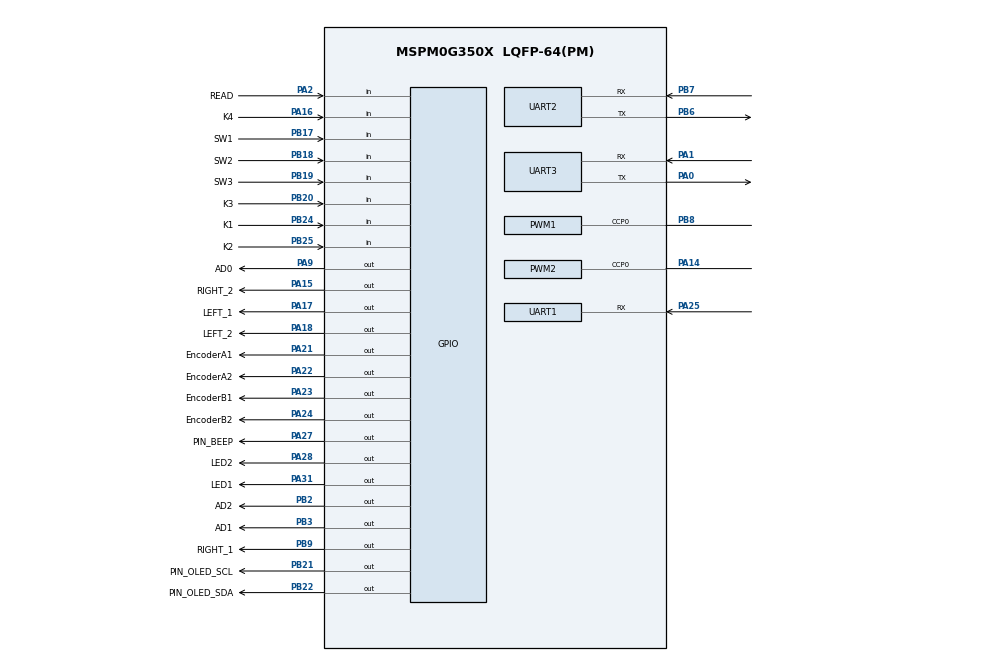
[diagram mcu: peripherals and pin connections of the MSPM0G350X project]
/**
 * @cliArgs --device "MSPM0G350X" --part "Default" --package "LQFP-64(PM)" --product "mspm0_sdk@2.10.00.04"
 * @versions {"tool":"1.26.2+4477"}
 */

/**
 * Import the modules used in this configuration.
 */
const GPIO   = scripting.addModule("/ti/driverlib/GPIO", {}, false);
const GPIO1  = GPIO.addInstance();
const GPIO2  = GPIO.addInstance();
const GPIO3  = GPIO.addInstance();
const GPIO4  = GPIO.addInstance();
const GPIO5  = GPIO.addInstance();
const GPIO6  = GPIO.addInstance();
const GPIO7  = GPIO.addInstance();
const GPIO8  = GPIO.addInstance();
const PWM    = scripting.addModule("/ti/driverlib/PWM", {}, false);
const PWM1   = PWM.addInstance();
const PWM2   = PWM.addInstance();
const SYSCTL = scripting.addModule("/ti/driverlib/SYSCTL");
const UART   = scripting.addModule("/ti/driverlib/UART", {}, false);
const UART1  = UART.addInstance();
const UART2  = UART.addInstance();
const UART3  = UART.addInstance();

/**
 * Write custom configuration values to the imported modules.
 */
const divider7       = system.clockTree["PLL_PDIV"];
divider7.divideValue = 2;

const divider9       = system.clockTree["UDIV"];
divider9.divideValue = 2;

const multiplier2         = system.clockTree["PLL_QDIV"];
multiplier2.multiplyValue = 5;

const mux8       = system.clockTree["HSCLKMUX"];
mux8.inputSelect = "HSCLKMUX_SYSPLL2X";

GPIO1.$name                          = "GPIO_MOTOR";
GPIO1.associatedPins.create(4);
GPIO1.associatedPins[0].$name        = "LEFT_1";
GPIO1.associatedPins[0].initialValue = "SET";
GPIO1.associatedPins[0].pin.$assign  = "PA17";
GPIO1.associatedPins[1].$name        = "LEFT_2";
GPIO1.associatedPins[1].pin.$assign  = "PA18";
GPIO1.associatedPins[2].$name        = "RIGHT_1";
GPIO1.associatedPins[2].pin.$assign  = "PB9";
GPIO1.associatedPins[3].$name        = "RIGHT_2";
GPIO1.associatedPins[3].pin.$assign  = "PA15";

const Board = scripting.addModule("/ti/driverlib/Board", {}, false);

GPIO2.$name                         = "GPIO_Grayscale";
GPIO2.associatedPins.create(4);
GPIO2.associatedPins[0].$name       = "READ";
GPIO2.associatedPins[0].direction   = "INPUT";
GPIO2.associatedPins[0].pin.$assign = "PA2";
GPIO2.associatedPins[1].$name       = "AD0";
GPIO2.associatedPins[1].pin.$assign = "PA9";
GPIO2.associatedPins[2].$name       = "AD1";
GPIO2.associatedPins[2].pin.$assign = "PB3";
GPIO2.associatedPins[3].$name       = "AD2";
GPIO2.associatedPins[3].pin.$assign = "PB2";

GPIO3.$name                         = "GPIO_BEEP";
GPIO3.associatedPins[0].$name       = "PIN_BEEP";
GPIO3.associatedPins[0].pin.$assign = "PA27";

GPIO4.$name                         = "GPIO_LED";
GPIO4.associatedPins.create(2);
GPIO4.associatedPins[0].$name       = "LED1";
GPIO4.associatedPins[0].pin.$assign = "PA31";
GPIO4.associatedPins[1].$name       = "LED2";
GPIO4.associatedPins[1].pin.$assign = "PA28";

GPIO5.$name                         = "GPIO_EncoderA";
GPIO5.associatedPins.create(2);
GPIO5.associatedPins[0].$name       = "EncoderA1";
GPIO5.associatedPins[0].pin.$assign = "PA21";
GPIO5.associatedPins[1].$name       = "EncoderA2";
GPIO5.associatedPins[1].pin.$assign = "PA22";

GPIO6.$name                         = "GPIO_EncoderB";
GPIO6.associatedPins.create(2);
GPIO6.associatedPins[0].$name       = "EncoderB1";
GPIO6.associatedPins[0].pin.$assign = "PA23";
GPIO6.associatedPins[1].$name       = "EncoderB2";
GPIO6.associatedPins[1].pin.$assign = "PA24";

GPIO7.$name                         = "GPIO_OLED";
GPIO7.associatedPins.create(2);
GPIO7.associatedPins[0].$name       = "PIN_OLED_SCL";
GPIO7.associatedPins[0].pin.$assign = "PB21";
GPIO7.associatedPins[1].$name       = "PIN_OLED_SDA";
GPIO7.associatedPins[1].pin.$assign = "PB22";

GPIO8.$name                         = "GPIO_KEY";
GPIO8.associatedPins.create(7);
GPIO8.associatedPins[0].$name       = "SW1";
GPIO8.associatedPins[0].direction   = "INPUT";
GPIO8.associatedPins[0].pin.$assign = "PB17";
GPIO8.associatedPins[1].$name       = "SW2";
GPIO8.associatedPins[1].direction   = "INPUT";
GPIO8.associatedPins[1].pin.$assign = "PB18";
GPIO8.associatedPins[2].$name       = "SW3";
GPIO8.associatedPins[2].direction   = "INPUT";
GPIO8.associatedPins[2].pin.$assign = "PB19";
GPIO8.associatedPins[3].$name       = "K1";
GPIO8.associatedPins[3].direction   = "INPUT";
GPIO8.associatedPins[3].pin.$assign = "PB24";
GPIO8.associatedPins[4].$name       = "K2";
GPIO8.associatedPins[4].direction   = "INPUT";
GPIO8.associatedPins[4].pin.$assign = "PB25";
GPIO8.associatedPins[5].$name       = "K3";
GPIO8.associatedPins[5].direction   = "INPUT";
GPIO8.associatedPins[5].pin.$assign = "PB20";
GPIO8.associatedPins[6].$name       = "K4";
GPIO8.associatedPins[6].direction   = "INPUT";
GPIO8.associatedPins[6].pin.$assign = "PA16";

PWM1.ccIndex                            = [0];
PWM1.$name                              = "PWM_A";
PWM1.timerStartTimer                    = true;
PWM1.pwmMode                            = "EDGE_ALIGN_UP";
PWM1.clockDivider                       = 8;
PWM1.PWM_CHANNEL_0.$name                = "ti_driverlib_pwm_PWMTimerCC2";
PWM1.ccp0PinConfig.direction            = scripting.forceWrite("OUTPUT");
PWM1.ccp0PinConfig.hideOutputInversion  = scripting.forceWrite(false);
PWM1.ccp0PinConfig.onlyInternalResistor = scripting.forceWrite(false);
PWM1.ccp0PinConfig.passedPeripheralType = scripting.forceWrite("Digital");
PWM1.ccp0PinConfig.$name                = "ti_driverlib_gpio_GPIOPinGeneric7";
PWM1.peripheral.$assign                 = "TIMA0";
PWM1.peripheral.ccp0Pin.$assign         = "PB8";

PWM2.ccIndex                            = [0];
PWM2.timerStartTimer                    = true;
PWM2.pwmMode                            = "EDGE_ALIGN_UP";
PWM2.$name                              = "PWM_B";
PWM2.clockDivider                       = 8;
PWM2.PWM_CHANNEL_0.$name                = "ti_driverlib_pwm_PWMTimerCC3";
PWM2.ccp0PinConfig.direction            = scripting.forceWrite("OUTPUT");
PWM2.ccp0PinConfig.hideOutputInversion  = scripting.forceWrite(false);
PWM2.ccp0PinConfig.onlyInternalResistor = scripting.forceWrite(false);
PWM2.ccp0PinConfig.passedPeripheralType = scripting.forceWrite("Digital");
PWM2.ccp0PinConfig.$name                = "ti_driverlib_gpio_GPIOPinGeneric8";
PWM2.peripheral.$assign                 = "TIMG12";
PWM2.peripheral.ccp0Pin.$assign         = "PA14";

SYSCTL.forceDefaultClkConfig = true;
SYSCTL.clockTreeEn           = true;

UART1.$name                            = "UART_WIT";
UART1.targetBaudRate                   = 115200;
UART1.direction                        = "RX";
UART1.enableFIFO                       = true;
UART1.rxTimeoutValue                   = 1;
UART1.enabledInterrupts                = ["RX_TIMEOUT_ERROR"];
UART1.enabledDMARXTriggers             = "DL_UART_DMA_INTERRUPT_RX";
UART1.rxPinConfig.hideOutputInversion  = scripting.forceWrite(false);
UART1.rxPinConfig.onlyInternalResistor = scripting.forceWrite(false);
UART1.rxPinConfig.passedPeripheralType = scripting.forceWrite("Digital");
UART1.rxPinConfig.$name                = "ti_driverlib_gpio_GPIOPinGeneric1";
UART1.peripheral.rxPin.$assign         = "PA25";
UART1.DMA_CHANNEL_RX.$name             = "DMA_WIT";
UART1.DMA_CHANNEL_RX.addressMode       = "f2b";
UART1.DMA_CHANNEL_RX.srcLength         = "BYTE";
UART1.DMA_CHANNEL_RX.dstLength         = "BYTE";

UART2.$name                            = "UART_VISION";
UART2.peripheral.$assign               = "UART1";
UART2.peripheral.rxPin.$assign         = "PB7";
UART2.peripheral.txPin.$assign         = "PB6";
UART2.txPinConfig.direction            = scripting.forceWrite("OUTPUT");
UART2.txPinConfig.hideOutputInversion  = scripting.forceWrite(false);
UART2.txPinConfig.onlyInternalResistor = scripting.forceWrite(false);
UART2.txPinConfig.passedPeripheralType = scripting.forceWrite("Digital");
UART2.txPinConfig.$name                = "ti_driverlib_gpio_GPIOPinGeneric2";
UART2.rxPinConfig.hideOutputInversion  = scripting.forceWrite(false);
UART2.rxPinConfig.onlyInternalResistor = scripting.forceWrite(false);
UART2.rxPinConfig.passedPeripheralType = scripting.forceWrite("Digital");
UART2.rxPinConfig.$name                = "ti_driverlib_gpio_GPIOPinGeneric3";

UART3.$name                            = "UART_BLUETEETH";
UART3.peripheral.$assign               = "UART0";
UART3.peripheral.rxPin.$assign         = "PA1";
UART3.peripheral.txPin.$assign         = "PA0";
UART3.txPinConfig.direction            = scripting.forceWrite("OUTPUT");
UART3.txPinConfig.hideOutputInversion  = scripting.forceWrite(false);
UART3.txPinConfig.onlyInternalResistor = scripting.forceWrite(false);
UART3.txPinConfig.passedPeripheralType = scripting.forceWrite("Digital");
UART3.txPinConfig.$name                = "ti_driverlib_gpio_GPIOPinGeneric4";
UART3.rxPinConfig.hideOutputInversion  = scripting.forceWrite(false);
UART3.rxPinConfig.onlyInternalResistor = scripting.forceWrite(false);
UART3.rxPinConfig.passedPeripheralType = scripting.forceWrite("Digital");
UART3.rxPinConfig.$name                = "ti_driverlib_gpio_GPIOPinGeneric5";

/**
 * Pinmux solution for unlocked pins/peripherals. This ensures that minor changes to the automatic solver in a future
 * version of the tool will not impact the pinmux you originally saw.  These lines can be completely deleted in order to
 * re-solve from scratch.
 */
Board.peripheral.$suggestSolution                = "DEBUGSS";
Board.peripheral.swclkPin.$suggestSolution       = "PA20";
Board.peripheral.swdioPin.$suggestSolution       = "PA19";
UART1.peripheral.$suggestSolution                = "UART3";
UART1.DMA_CHANNEL_RX.peripheral.$suggestSolution = "DMA_CH0";
